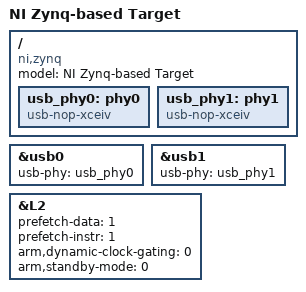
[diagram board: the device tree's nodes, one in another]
/include/ "zynq-7000.dtsi"

/ {
	model = "NI Zynq-based Target";
	compatible = "ni,zynq", "xlnx,zynq-7000";

	usb_phy0: phy0 {
		compatible = "usb-nop-xceiv";
		#phy-cells = <0>;
	};

	usb_phy1: phy1 {
		compatible = "usb-nop-xceiv";
		#phy-cells = <0>;
	};
};

&usb0 {
	usb-phy = <&usb_phy0>;
};

&usb1 {
	usb-phy = <&usb_phy1>;
};

&L2 {
	prefetch-data = <1>;
	prefetch-instr = <1>;
	arm,dynamic-clock-gating = <0>;
	arm,standby-mode = <0>;
};
